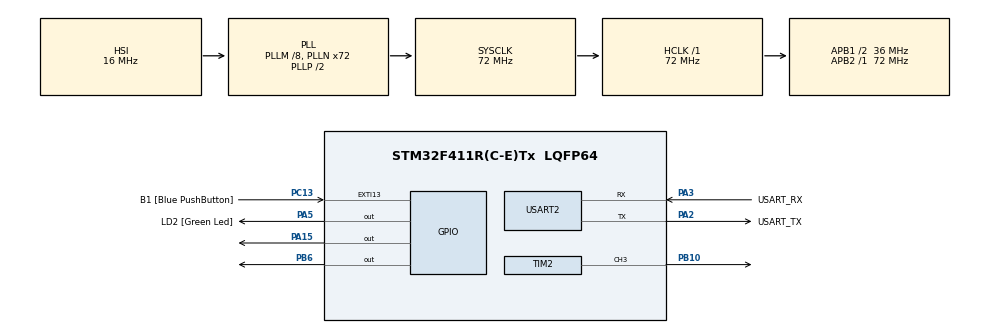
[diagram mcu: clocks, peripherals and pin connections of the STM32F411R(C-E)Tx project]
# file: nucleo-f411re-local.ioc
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FREERTOS.Events01=Button01,Dynamic,NULL
FREERTOS.Tasks01=Blink01,24,128,StartBlink01,Default,NULL,Dynamic,NULL,NULL;Servo00,40,128,Servo00_Control,Default,degree,Dynamic,NULL,NULL
FREERTOS.configUSE_NEWLIB_REENTRANT=1
Mcu.Family=STM32F4
Mcu.Name=STM32F411R(C-E)Tx
Mcu.Package=LQFP64
NVIC.PriorityGroup=NVIC_PRIORITYGROUP_4
NVIC.TIM3_IRQn=true\:15\:0\:false\:false\:true\:false\:false\:true\:true
NVIC.TimeBase=TIM3_IRQn
NVIC.TimeBaseIP=TIM3
PA13.GPIO_Label=TMS
PA13.Mode=Serial_Wire
PA13.Signal=SYS_JTMS-SWDIO
PA14.GPIO_Label=TCK
PA14.Mode=Serial_Wire
PA14.Signal=SYS_JTCK-SWCLK
PA15.PinState=GPIO_PIN_SET
PA15.Signal=GPIO_Output
PA2.GPIO_Label=USART_TX
PA2.Mode=Asynchronous
PA2.Signal=USART2_TX
PA3.GPIO_Label=USART_RX
PA3.Mode=Asynchronous
PA3.Signal=USART2_RX
PA5.GPIO_Label=LD2 [Green Led]
PA5.Signal=GPIO_Output
PB10.Signal=S_TIM2_CH3
PB3.GPIO_Label=SWO
PB3.Signal=SYS_JTDO-SWO
PB6.Signal=GPIO_Output
PC13-ANTI_TAMP.GPIO_Label=B1 [Blue PushButton]
PC13-ANTI_TAMP.GPIO_ModeDefaultEXTI=GPIO_MODE_IT_FALLING
PC13-ANTI_TAMP.Signal=GPXTI13
PC14-OSC32_IN.Mode=LSE-External-Oscillator
PC14-OSC32_IN.Signal=RCC_OSC32_IN
PC15-OSC32_OUT.Mode=LSE-External-Oscillator
PC15-OSC32_OUT.Signal=RCC_OSC32_OUT
PH0\ -\ OSC_IN.Mode=HSE-External-Oscillator
PH0\ -\ OSC_IN.Signal=RCC_OSC_IN
PH1\ -\ OSC_OUT.Mode=HSE-External-Oscillator
PH1\ -\ OSC_OUT.Signal=RCC_OSC_OUT
ProjectManager.HeapSize=0x200
ProjectManager.StackSize=0x400
ProjectManager.TargetToolchain=STM32CubeIDE
RCC.48MHZClocksFreq_Value=36000000
RCC.AHBFreq_Value=72000000
RCC.APB1CLKDivider=RCC_HCLK_DIV2
RCC.APB1Freq_Value=36000000
RCC.APB1TimFreq_Value=72000000
RCC.APB2Freq_Value=72000000
RCC.APB2TimFreq_Value=72000000
RCC.CortexFreq_Value=72000000
RCC.FLatency-AdvancedSettings=FLASH_LATENCY_2
RCC.HCLKFreq_Value=72000000
RCC.HSE_VALUE=8000000
RCC.HSI_VALUE=16000000
RCC.PLLM=8
RCC.PLLN=72
RCC.SYSCLKFreq_VALUE=72000000
RCC.SYSCLKSource=RCC_SYSCLKSOURCE_PLLCLK
RCC.VCOOutputFreq_Value=144000000
SH.S_TIM2_CH3.0=TIM2_CH3,PWM Generation3 CH3
TIM2.AutoReloadPreload=TIM_AUTORELOAD_PRELOAD_DISABLE
TIM2.Channel-PWM\ Generation3\ CH3=TIM_CHANNEL_3
TIM2.Period=19999
TIM2.Prescaler=71
TIM2.Pulse-PWM\ Generation3\ CH3=500
USART2.VirtualMode=VM_ASYNC
VP_FREERTOS_VS_CMSIS_V2.Mode=CMSIS_V2
VP_SYS_VS_tim3.Mode=TIM3
VP_TIM2_VS_ClockSourceINT.Mode=Internal
board=NUCLEO-F411RE

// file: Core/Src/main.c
/* USER CODE BEGIN Header */
/**
  ******************************************************************************
  * @file           : main.c
  * @brief          : Main program body
  ******************************************************************************
  * @attention
  *
  * Copyright (c) 2024 STMicroelectronics.
  * All rights reserved.
  *
  * This software is licensed under terms that can be found in the LICENSE file
  * in the root directory of this software component.
  * If no LICENSE file comes with this software, it is provided AS-IS.
  *
  ******************************************************************************
  */
/* USER CODE END Header */
#include "main.h"
#include "cmsis_os.h"

TIM_HandleTypeDef htim2;

UART_HandleTypeDef huart2;

/* Definitions for Blink01 */
osThreadId_t Blink01Handle;
const osThreadAttr_t Blink01_attributes = {
  .name = "Blink01",
  .stack_size = 128 * 4,
  .priority = (osPriority_t) osPriorityNormal,
};
/* Definitions for Servo00 */
osThreadId_t Servo00Handle;
const osThreadAttr_t Servo00_attributes = {
  .name = "Servo00",
  .stack_size = 128 * 4,
  .priority = (osPriority_t) osPriorityHigh,
};
/* Definitions for Button01 */
osEventFlagsId_t Button01Handle;
const osEventFlagsAttr_t Button01_attributes = {
  .name = "Button01"
};
/* USER CODE BEGIN PV */
void setPWM(uint16_t);
void PWMRotate(int16_t);
/* USER CODE END PV */

void SystemClock_Config(void);
static void MX_GPIO_Init(void);
static void MX_USART2_UART_Init(void);
static void MX_TIM2_Init(void);
void StartBlink01(void *argument);
void Servo00_Control(void *argument);

int main(void)
{

  /* MCU Configuration--------------------------------------------------------*/

  /* Reset of all peripherals, Initializes the Flash interface and the Systick. */
  HAL_Init();

  /* Configure the system clock */
  SystemClock_Config();

  /* Initialize all configured peripherals */
  MX_GPIO_Init();
  MX_USART2_UART_Init();
  MX_TIM2_Init();

  /* Init scheduler */
  osKernelInitialize();

  /* Create the thread(s) */
  /* creation of Blink01 */
  Blink01Handle = osThreadNew(StartBlink01, NULL, &Blink01_attributes);

  /* creation of Servo00 */
  int degree = 1500;
  Servo00Handle = osThreadNew(Servo00_Control, (void*) degree, &Servo00_attributes);

  /* USER CODE BEGIN RTOS_THREADS */
  /* add threads, ... */
  HAL_TIM_PWM_Start(&htim2, TIM_CHANNEL_3);
  /* USER CODE END RTOS_THREADS */

  /* Create the event(s) */
  /* creation of Button01 */
  Button01Handle = osEventFlagsNew(&Button01_attributes);

  /* Start scheduler */
  osKernelStart();

  /* We should never get here as control is now taken by the scheduler */
  /* Infinite loop */
  while (1)
  {

  }
}

void SystemClock_Config(void)
{
  RCC_OscInitTypeDef RCC_OscInitStruct = {0};
  RCC_ClkInitTypeDef RCC_ClkInitStruct = {0};

  /** Configure the main internal regulator output voltage
  */
  __HAL_RCC_PWR_CLK_ENABLE();
  __HAL_PWR_VOLTAGESCALING_CONFIG(PWR_REGULATOR_VOLTAGE_SCALE1);

  /** Initializes the RCC Oscillators according to the specified parameters
  * in the RCC_OscInitTypeDef structure.
  */
  RCC_OscInitStruct.OscillatorType = RCC_OSCILLATORTYPE_HSI;
  RCC_OscInitStruct.HSIState = RCC_HSI_ON;
  RCC_OscInitStruct.HSICalibrationValue = RCC_HSICALIBRATION_DEFAULT;
  RCC_OscInitStruct.PLL.PLLState = RCC_PLL_ON;
  RCC_OscInitStruct.PLL.PLLSource = RCC_PLLSOURCE_HSI;
  RCC_OscInitStruct.PLL.PLLM = 8;
  RCC_OscInitStruct.PLL.PLLN = 72;
  RCC_OscInitStruct.PLL.PLLP = RCC_PLLP_DIV2;
  RCC_OscInitStruct.PLL.PLLQ = 4;
  if (HAL_RCC_OscConfig(&RCC_OscInitStruct) != HAL_OK)
  {
    Error_Handler();
  }

  /** Initializes the CPU, AHB and APB buses clocks
  */
  RCC_ClkInitStruct.ClockType = RCC_CLOCKTYPE_HCLK|RCC_CLOCKTYPE_SYSCLK
                              |RCC_CLOCKTYPE_PCLK1|RCC_CLOCKTYPE_PCLK2;
  RCC_ClkInitStruct.SYSCLKSource = RCC_SYSCLKSOURCE_PLLCLK;
  RCC_ClkInitStruct.AHBCLKDivider = RCC_SYSCLK_DIV1;
  RCC_ClkInitStruct.APB1CLKDivider = RCC_HCLK_DIV2;
  RCC_ClkInitStruct.APB2CLKDivider = RCC_HCLK_DIV1;

  if (HAL_RCC_ClockConfig(&RCC_ClkInitStruct, FLASH_LATENCY_2) != HAL_OK)
  {
    Error_Handler();
  }
}

static void MX_TIM2_Init(void)
{

  TIM_ClockConfigTypeDef sClockSourceConfig = {0};
  TIM_MasterConfigTypeDef sMasterConfig = {0};
  TIM_OC_InitTypeDef sConfigOC = {0};

  htim2.Instance = TIM2;
  htim2.Init.Prescaler = 71;
  htim2.Init.CounterMode = TIM_COUNTERMODE_UP;
  htim2.Init.Period = 19999;
  htim2.Init.ClockDivision = TIM_CLOCKDIVISION_DIV1;
  htim2.Init.AutoReloadPreload = TIM_AUTORELOAD_PRELOAD_DISABLE;
  if (HAL_TIM_Base_Init(&htim2) != HAL_OK)
  {
    Error_Handler();
  }
  sClockSourceConfig.ClockSource = TIM_CLOCKSOURCE_INTERNAL;
  if (HAL_TIM_ConfigClockSource(&htim2, &sClockSourceConfig) != HAL_OK)
  {
    Error_Handler();
  }
  if (HAL_TIM_PWM_Init(&htim2) != HAL_OK)
  {
    Error_Handler();
  }
  sMasterConfig.MasterOutputTrigger = TIM_TRGO_RESET;
  sMasterConfig.MasterSlaveMode = TIM_MASTERSLAVEMODE_DISABLE;
  if (HAL_TIMEx_MasterConfigSynchronization(&htim2, &sMasterConfig) != HAL_OK)
  {
    Error_Handler();
  }
  sConfigOC.OCMode = TIM_OCMODE_PWM1;
  sConfigOC.Pulse = 500;
  sConfigOC.OCPolarity = TIM_OCPOLARITY_HIGH;
  sConfigOC.OCFastMode = TIM_OCFAST_DISABLE;
  if (HAL_TIM_PWM_ConfigChannel(&htim2, &sConfigOC, TIM_CHANNEL_3) != HAL_OK)
  {
    Error_Handler();
  }
  HAL_TIM_MspPostInit(&htim2);

}

static void MX_USART2_UART_Init(void)
{

  huart2.Instance = USART2;
  huart2.Init.BaudRate = 115200;
  huart2.Init.WordLength = UART_WORDLENGTH_8B;
  huart2.Init.StopBits = UART_STOPBITS_1;
  huart2.Init.Parity = UART_PARITY_NONE;
  huart2.Init.Mode = UART_MODE_TX_RX;
  huart2.Init.HwFlowCtl = UART_HWCONTROL_NONE;
  huart2.Init.OverSampling = UART_OVERSAMPLING_16;
  if (HAL_UART_Init(&huart2) != HAL_OK)
  {
    Error_Handler();
  }

}

static void MX_GPIO_Init(void)
{
  GPIO_InitTypeDef GPIO_InitStruct = {0};

  /* GPIO Ports Clock Enable */
  __HAL_RCC_GPIOC_CLK_ENABLE();
  __HAL_RCC_GPIOH_CLK_ENABLE();
  __HAL_RCC_GPIOA_CLK_ENABLE();
  __HAL_RCC_GPIOB_CLK_ENABLE();

  /*Configure GPIO pin Output Level */
  HAL_GPIO_WritePin(LD2_GPIO_Port, LD2_Pin, GPIO_PIN_RESET);

  /*Configure GPIO pin Output Level */
  HAL_GPIO_WritePin(GPIOA, GPIO_PIN_15, GPIO_PIN_SET);

  /*Configure GPIO pin Output Level */
  HAL_GPIO_WritePin(GPIOB, GPIO_PIN_6, GPIO_PIN_RESET);

  /*Configure GPIO pin : B1_Pin */
  GPIO_InitStruct.Pin = B1_Pin;
  GPIO_InitStruct.Mode = GPIO_MODE_IT_FALLING;
  GPIO_InitStruct.Pull = GPIO_NOPULL;
  HAL_GPIO_Init(B1_GPIO_Port, &GPIO_InitStruct);

  /*Configure GPIO pins : LD2_Pin PA15 */
  GPIO_InitStruct.Pin = LD2_Pin|GPIO_PIN_15;
  GPIO_InitStruct.Mode = GPIO_MODE_OUTPUT_PP;
  GPIO_InitStruct.Pull = GPIO_NOPULL;
  GPIO_InitStruct.Speed = GPIO_SPEED_FREQ_LOW;
  HAL_GPIO_Init(GPIOA, &GPIO_InitStruct);

  /*Configure GPIO pin : PB6 */
  GPIO_InitStruct.Pin = GPIO_PIN_6;
  GPIO_InitStruct.Mode = GPIO_MODE_OUTPUT_PP;
  GPIO_InitStruct.Pull = GPIO_NOPULL;
  GPIO_InitStruct.Speed = GPIO_SPEED_FREQ_LOW;
  HAL_GPIO_Init(GPIOB, &GPIO_InitStruct);

}

void StartBlink01(void *argument)
{
  /* USER CODE BEGIN 5 */
  /* Infinite loop */
  for(;;)
  {
	HAL_GPIO_TogglePin(GPIOA, GPIO_PIN_5);
    osDelay(500);
    if (!HAL_GPIO_ReadPin(GPIOC, GPIO_PIN_13))
    {
    	osThreadSuspend(Blink01Handle);
    }
//    osThreadResume(Blink01Handle);
  }
  /* USER CODE END 5 */
}

void Servo00_Control(void *argument)
{
  /* USER CODE BEGIN Servo00_Control */
	int *degree;
	degree = (int*) argument;
  /* Infinite loop */
  for(;;)
  {
	__HAL_TIM_SET_COMPARE(&htim2, TIM_CHANNEL_3, degree);
	HAL_Delay(2000);
	__HAL_TIM_SET_COMPARE(&htim2, TIM_CHANNEL_3, 500);
	HAL_Delay(2000);
    osDelay(4000);
  }
  /* USER CODE END Servo00_Control */
}

void HAL_TIM_PeriodElapsedCallback(TIM_HandleTypeDef *htim)
{
  if (htim->Instance == TIM3) {
    HAL_IncTick();
  }
}

void Error_Handler(void)
{
  __disable_irq();
  while (1)
  {
  }
}
